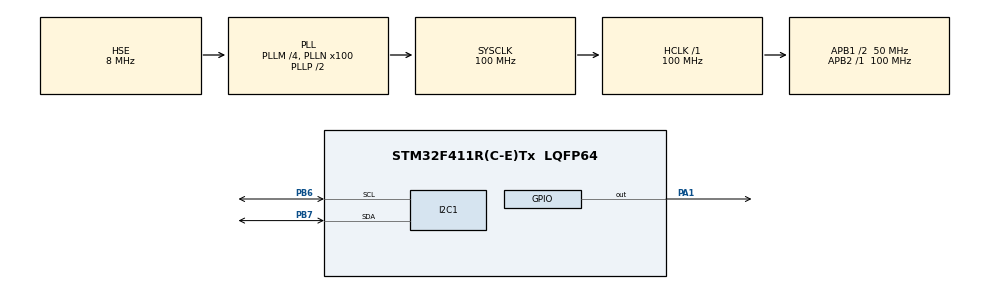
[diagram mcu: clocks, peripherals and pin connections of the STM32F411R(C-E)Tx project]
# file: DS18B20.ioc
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Mcu.Family=STM32F4
Mcu.Name=STM32F411R(C-E)Tx
Mcu.Package=LQFP64
NVIC.PriorityGroup=NVIC_PRIORITYGROUP_4
PA1.Signal=GPIO_Output
PA13.Mode=Serial_Wire
PA13.Signal=SYS_JTMS-SWDIO
PA14.Mode=Serial_Wire
PA14.Signal=SYS_JTCK-SWCLK
PB6.Mode=I2C
PB6.Signal=I2C1_SCL
PB7.Mode=I2C
PB7.Signal=I2C1_SDA
PH0\ -\ OSC_IN.Mode=HSE-External-Oscillator
PH0\ -\ OSC_IN.Signal=RCC_OSC_IN
PH1\ -\ OSC_OUT.Mode=HSE-External-Oscillator
PH1\ -\ OSC_OUT.Signal=RCC_OSC_OUT
ProjectManager.HeapSize=0x200
ProjectManager.StackSize=0x400
ProjectManager.TargetToolchain=STM32CubeIDE
RCC.48MHZClocksFreq_Value=50000000
RCC.AHBFreq_Value=100000000
RCC.APB1CLKDivider=RCC_HCLK_DIV2
RCC.APB1Freq_Value=50000000
RCC.APB1TimFreq_Value=100000000
RCC.APB2Freq_Value=100000000
RCC.APB2TimFreq_Value=100000000
RCC.CortexFreq_Value=100000000
RCC.HCLKFreq_Value=100000000
RCC.HSE_VALUE=8000000
RCC.HSI_VALUE=16000000
RCC.LSE_VALUE=32768
RCC.PLLM=4
RCC.PLLN=100
RCC.PLLSourceVirtual=RCC_PLLSOURCE_HSE
RCC.SYSCLKFreq_VALUE=100000000
RCC.SYSCLKSource=RCC_SYSCLKSOURCE_PLLCLK
RCC.VCOOutputFreq_Value=200000000
TIM10.Prescaler=100-1
VP_TIM10_VS_ClockSourceINT.Mode=Enable_Timer
board=custom

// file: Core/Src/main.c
/* USER CODE BEGIN Header */
/**
  ******************************************************************************
  * @file           : main.c
  * @brief          : Main program body
  ******************************************************************************
  * @attention
  *
  * Copyright (c) 2023 STMicroelectronics.
  * All rights reserved.
  *
  * This software is licensed under terms that can be found in the LICENSE file
  * in the root directory of this software component.
  * If no LICENSE file comes with this software, it is provided AS-IS.
  *
  ******************************************************************************
  */
/* USER CODE END Header */
#include "main.h"
#include "i2c.h"
#include "tim.h"
#include "gpio.h"

/* USER CODE BEGIN Includes */
#include "stdio.h"
#include "I2C_LCD.h"
#include "delay.h"
/* USER CODE END Includes */

/* USER CODE BEGIN PM */
#define DS18B20_PORT GPIOA
#define DS18B20_PIN GPIO_PIN_1
/* USER CODE END PM */

/* USER CODE BEGIN PV */
uint8_t Rh_byte1, Rh_byte2, Temp_byte1, Temp_byte2;
uint16_t SUM, RH, TEMP;

float Temperature = 0.0;
uint8_t Presense = 0;
/* USER CODE END PV */

void SystemClock_Config(void);
/* USER CODE BEGIN PFP */
void Set_Pin_Output(GPIO_TypeDef *, uint16_t);
void Set_Pin_Input(GPIO_TypeDef *, uint16_t);

uint8_t DS18B20_start();

void DS18B20_Write(uint8_t);
uint8_t DS18B20_Read();
/* USER CODE END PFP */

int main(void)
{

  /* MCU Configuration--------------------------------------------------------*/

  /* Reset of all peripherals, Initializes the Flash interface and the Systick. */
  HAL_Init();

  /* Configure the system clock */
  SystemClock_Config();

  /* Initialize all configured peripherals */
  MX_GPIO_Init();
  MX_I2C1_Init();
  MX_TIM10_Init();
  /* USER CODE BEGIN 2 */
  HAL_TIM_Base_Start(&htim10);

  LCD_init();
  /* USER CODE END 2 */

  /* Infinite loop */
  /* USER CODE BEGIN WHILE */
  uint8_t rxDataL, rxDataH;
  float temperature;
  char buffer[17];

  while (1)
  {
    /* USER CODE END WHILE */

    /* USER CODE BEGIN 3 */
    DS18B20_start();
    DS18B20_Write(0xcc);
    DS18B20_Write(0x44);

    DS18B20_start();
    DS18B20_Write(0xcc);
    DS18B20_Write(0xbe);

    rxDataL = DS18B20_Read();
    rxDataH = DS18B20_Read();
    temperature = (float)(rxDataH << 8 | rxDataL) / 16.;

    sprintf(buffer, "T: %.1f  ", temperature);
    LCD_put_cursor(0, 0);
    LCD_send_str(buffer);
    HAL_Delay(200);
  }
  /* USER CODE END 3 */
}

void SystemClock_Config(void)
{
  RCC_OscInitTypeDef RCC_OscInitStruct = {0};
  RCC_ClkInitTypeDef RCC_ClkInitStruct = {0};

  /** Configure the main internal regulator output voltage
  */
  __HAL_RCC_PWR_CLK_ENABLE();
  __HAL_PWR_VOLTAGESCALING_CONFIG(PWR_REGULATOR_VOLTAGE_SCALE1);

  /** Initializes the RCC Oscillators according to the specified parameters
  * in the RCC_OscInitTypeDef structure.
  */
  RCC_OscInitStruct.OscillatorType = RCC_OSCILLATORTYPE_HSE;
  RCC_OscInitStruct.HSEState = RCC_HSE_ON;
  RCC_OscInitStruct.PLL.PLLState = RCC_PLL_ON;
  RCC_OscInitStruct.PLL.PLLSource = RCC_PLLSOURCE_HSE;
  RCC_OscInitStruct.PLL.PLLM = 4;
  RCC_OscInitStruct.PLL.PLLN = 100;
  RCC_OscInitStruct.PLL.PLLP = RCC_PLLP_DIV2;
  RCC_OscInitStruct.PLL.PLLQ = 4;
  if (HAL_RCC_OscConfig(&RCC_OscInitStruct) != HAL_OK)
  {
    Error_Handler();
  }

  /** Initializes the CPU, AHB and APB buses clocks
  */
  RCC_ClkInitStruct.ClockType = RCC_CLOCKTYPE_HCLK|RCC_CLOCKTYPE_SYSCLK
                              |RCC_CLOCKTYPE_PCLK1|RCC_CLOCKTYPE_PCLK2;
  RCC_ClkInitStruct.SYSCLKSource = RCC_SYSCLKSOURCE_PLLCLK;
  RCC_ClkInitStruct.AHBCLKDivider = RCC_SYSCLK_DIV1;
  RCC_ClkInitStruct.APB1CLKDivider = RCC_HCLK_DIV2;
  RCC_ClkInitStruct.APB2CLKDivider = RCC_HCLK_DIV1;

  if (HAL_RCC_ClockConfig(&RCC_ClkInitStruct, FLASH_LATENCY_3) != HAL_OK)
  {
    Error_Handler();
  }
}

/* USER CODE BEGIN 4 */
void Set_Pin_Output(GPIO_TypeDef *GPIOx, uint16_t GPIO_Pin) {
    GPIO_InitTypeDef GPIO_InitStruct = {0};
    GPIO_InitStruct.Pin = GPIO_Pin;
    GPIO_InitStruct.Mode = GPIO_MODE_OUTPUT_PP;
    GPIO_InitStruct.Pull = GPIO_NOPULL;
    GPIO_InitStruct.Speed = GPIO_SPEED_FREQ_LOW;
    HAL_GPIO_Init(GPIOx, &GPIO_InitStruct);
}
void Set_Pin_Input(GPIO_TypeDef *GPIOx, uint16_t GPIO_Pin) {
    GPIO_InitTypeDef GPIO_InitStruct = {0};
    GPIO_InitStruct.Pin = GPIO_Pin;
    GPIO_InitStruct.Mode = GPIO_MODE_INPUT;
    GPIO_InitStruct.Pull = GPIO_NOPULL;
    HAL_GPIO_Init(GPIOx, &GPIO_InitStruct);
}

uint8_t DS18B20_start() {
    uint8_t response = 0;
    Set_Pin_Output(DS18B20_PORT, DS18B20_PIN);
    HAL_GPIO_WritePin(DS18B20_PORT, DS18B20_PIN, GPIO_PIN_RESET);
    delay_us(480);

    Set_Pin_Input(DS18B20_PORT, DS18B20_PIN);
    delay_us(60);

    if (!HAL_GPIO_ReadPin(DS18B20_PORT, DS18B20_PIN)) {
        response = 1;
    }
    delay_us(420);

    return response;
}

void DS18B20_Write(uint8_t cmd) {
    for (uint8_t idx = 0; idx < 8; idx++) {
        if (cmd & 1 << idx) {
            Set_Pin_Output(DS18B20_PORT, DS18B20_PIN);
            HAL_GPIO_WritePin(DS18B20_PORT, DS18B20_PIN, GPIO_PIN_RESET);
            delay_us(1);

            Set_Pin_Input(DS18B20_PORT, DS18B20_PIN);
            delay_us(60);
        }
        else {
            Set_Pin_Output(DS18B20_PORT, DS18B20_PIN);
            HAL_GPIO_WritePin(DS18B20_PORT, DS18B20_PIN, GPIO_PIN_RESET);
            delay_us(60);

            Set_Pin_Input(DS18B20_PORT, DS18B20_PIN);
            delay_us(1);
        }
    }
}
uint8_t DS18B20_Read() {
    uint8_t data = 0x00;

    for (uint8_t idx = 0; idx < 8; idx++) {
        Set_Pin_Output(DS18B20_PORT, DS18B20_PIN);
        delay_us(1);

        Set_Pin_Input(DS18B20_PORT, DS18B20_PIN);
        delay_us(13);
        if (HAL_GPIO_ReadPin(DS18B20_PORT, DS18B20_PIN)) {
            data |= 1 << idx;
        }
        delay_us(47);
    }

    return data;
}
/* USER CODE END 4 */

void Error_Handler(void)
{
  __disable_irq();
  while (1)
  {
  }
}
